# R7FA2A2AD register map
Vendor: Renesas Electronics Corporation; Series: RA2A2; File version: 1.20.02
CPU: CM23 r1p0, little endian, MPU, no FPU, VTOR, 2 interrupt priority bits, 32 interrupts
Registers are 8-bit, read-write, reset 0x0 unless marked. A register's access mark holds for its fields unless they carry their own. Offsets are from the block's base; [hi:lo] are bit positions; {n}, {i} and the like mark numbered series; 'fields as' and 'values as' point back to an identical list.

## RMPU — Renesas Memory Protection Unit
Base 0x40000000
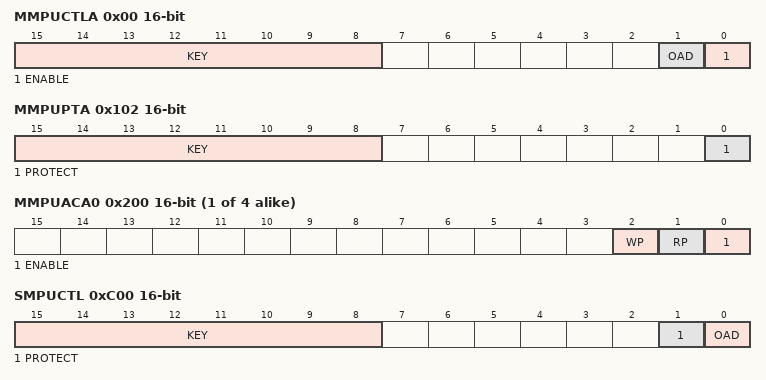
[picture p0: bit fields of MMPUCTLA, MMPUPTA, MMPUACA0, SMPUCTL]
0x00 MMPUCTLA 16-bit — Bus Master MPU Control Register
  [15:8] KEY — Key Code
  [1] OAD — Operation After Detection
  [0] ENABLE — Master Group Enable
0x102 MMPUPTA 16-bit — Group A Protection of Register
  [15:8] KEY — Key Code
  [0] PROTECT — Protection of Register
{0x200+0x10*i} MMPUACA{i} (i=0..3) 16-bit — Group A Region {i} Access Control Register
  [2] WP — Write Protection
  [1] RP — Read Protection
  [0] ENABLE — Region Enable
{0x204+0x10*i} MMPUSA{i} (i=0..3) 32-bit (reset mask 0x3) — Group A Region {i} Start Address Register
  [31:0] MMPUSA — Region Start Address
{0x208+0x10*i} MMPUEA{i} (i=0..3) 32-bit reset 0x3 (reset mask 0x3) — Group A Region {i} End Address Register
  [31:0] MMPUEA — Region End Address
0xC00 SMPUCTL 16-bit — Slave MPU Control Register
  [15:8] KEY — Key Code
  [1] PROTECT — Protection of Register
  [0] OAD — Operation After Detection
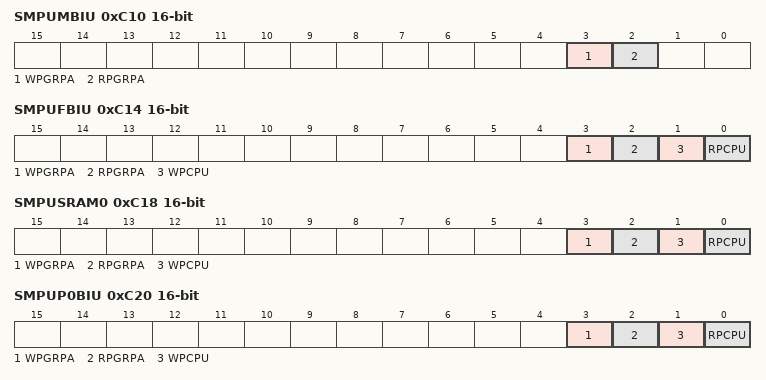
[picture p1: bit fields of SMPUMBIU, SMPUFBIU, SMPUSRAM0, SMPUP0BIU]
0xC10 SMPUMBIU 16-bit — Access Control Register for Memory Bus 1
  [3] WPGRPA — Master MPU Group A Write Protection
  [2] RPGRPA — Master MPU Group A Read Protection
0xC14 SMPUFBIU 16-bit — Access Control Register for Internal Peripheral Bus 9
  [3] WPGRPA — Master MPU Group A Write Protection
  [2] RPGRPA — Master MPU Group A Read Protection
  [1] WPCPU — CPU Write Protection
  [0] RPCPU — CPU Read Protection
0xC18 SMPUSRAM0 16-bit — Access Control Register for Memory Bus 4
  fields as SMPUFBIU
0xC20 SMPUP0BIU 16-bit — Access Control Register for Internal Peripheral Bus 1
  fields as SMPUFBIU
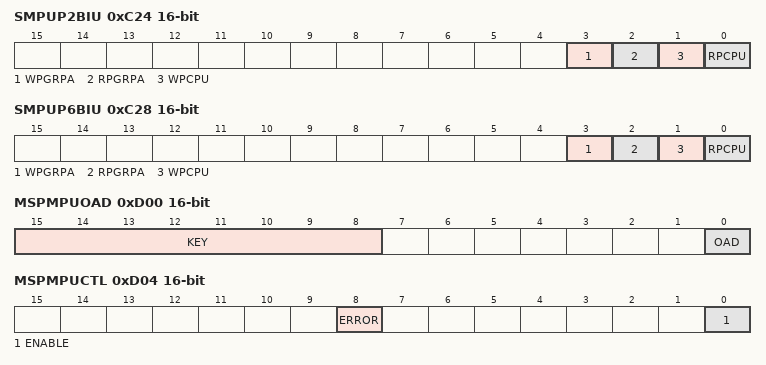
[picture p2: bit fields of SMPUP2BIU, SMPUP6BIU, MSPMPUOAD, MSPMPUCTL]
0xC24 SMPUP2BIU 16-bit — Access Control Register for Internal Peripheral Bus 3
  fields as SMPUFBIU
0xC28 SMPUP6BIU 16-bit — Access Control Register for Internal Peripheral Bus 7
  fields as SMPUFBIU
0xD00 MSPMPUOAD 16-bit — Stack Pointer Monitor Operation After Detection Register
  [15:8] KEY — Key Code
  [0] OAD — Operation after Detection
0xD04 MSPMPUCTL 16-bit (reset mask 0xFEFF) — Stack Pointer Monitor Access Control Register
  [8] ERROR — Stack Pointer Monitor Error Flag
  [0] ENABLE — Stack Pointer Monitor Enable
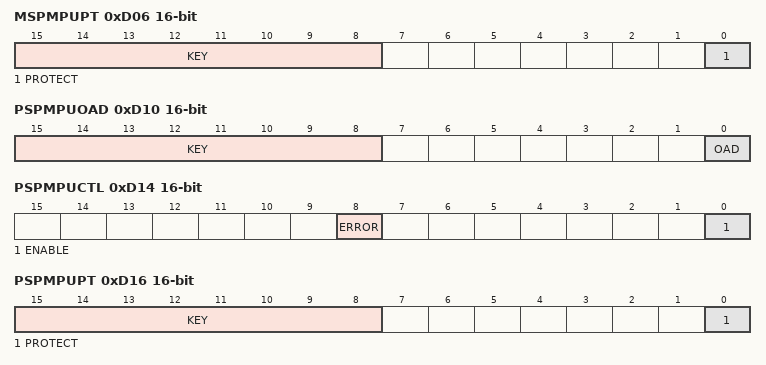
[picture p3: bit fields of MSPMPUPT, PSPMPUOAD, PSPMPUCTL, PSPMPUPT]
0xD06 MSPMPUPT 16-bit — Stack Pointer Monitor Protection Register
  [15:8] KEY — Key Code
  [0] PROTECT — Protection of Register
0xD08 MSPMPUSA 32-bit reset not defined — Main Stack Pointer (MSP) Monitor Start Address Register
  [31:0] MSPMPUSA — Region Start Address
0xD0C MSPMPUEA 32-bit reset not defined — Main Stack Pointer (MSP) Monitor End Address Register
  [31:0] MSPMPUEA — Region End Address
0xD10 PSPMPUOAD 16-bit — Stack Pointer Monitor Operation After Detection Register
  [15:8] KEY — Key Code
  [0] OAD — Operation after Detection
0xD14 PSPMPUCTL 16-bit (reset mask 0xFEFF) — Stack Pointer Monitor Access Control Register
  fields as MSPMPUCTL
0xD16 PSPMPUPT 16-bit — Stack Pointer Monitor Protection Register
  [15:8] KEY — Key Code
  [0] PROTECT — Protection of Register
0xD18 PSPMPUSA 32-bit reset not defined — Process Stack Pointer (PSP) Monitor Start Address Register
  [31:0] PSPMPUSA range 0x1FF00000..0x200FFFFC — Region Start Address
0xD1C PSPMPUEA 32-bit reset not defined — Process Stack Pointer (PSP) Monitor End Address Register
  [31:0] PSPMPUEA range 0x1FF00003..0x200FFFFF — Region End Address

## MMF — Memory Mirror Function
Base 0x40001000
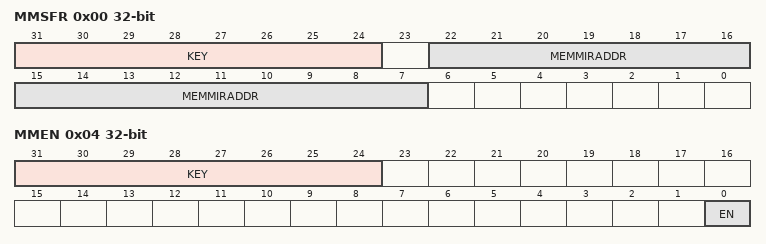
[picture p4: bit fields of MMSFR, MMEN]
0x00 MMSFR 32-bit — MemMirror Special Function Register
  [31:24] KEY wo — MMSFR Key Code
  [22:7] MEMMIRADDR — Memory Mirror Address
0x04 MMEN 32-bit — MemMirror Enable Register
  [31:24] KEY wo — MMEN Key Code
  [0] EN — Memory Mirror Function Enable

## SRAM — SRAM Control
Base 0x40002000
0x00 PARIOAD — SRAM Parity Error Operation After Detection Register
  [0] OAD — Operation After Detection
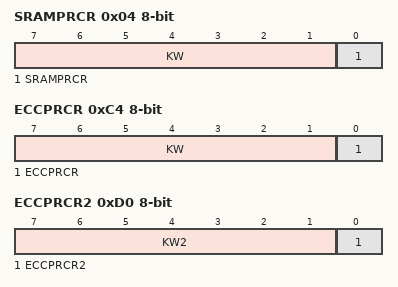
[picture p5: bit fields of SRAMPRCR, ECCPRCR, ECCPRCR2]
0x04 SRAMPRCR — SRAM Protection Register
  [7:1] KW wo — Write Key Code
  [0] SRAMPRCR — Register Write Control
0xC0 ECCMODE — ECC Operating Mode Control Register
  [1:0] ECCMOD — ECC Operating Mode Select
0xC1 ECC2STS — ECC 2-Bit Error Status Register
  [0] ECC2ERR — ECC 2-Bit Error Status
0xC2 ECC1STSEN — ECC 1-Bit Error Information Update Enable Register
  [0] E1STSEN — ECC 1-Bit Error Information Update Enable
0xC3 ECC1STS — ECC 1-Bit Error Status Register
  [0] ECC1ERR — ECC 1-Bit Error Status
0xC4 ECCPRCR — ECC Protection Register
  [7:1] KW wo — Write Key Code
  [0] ECCPRCR — Register Write Control
0xD0 ECCPRCR2 — ECC Protection Register 2
  [7:1] KW2 wo — Write Key Code
  [0] ECCPRCR2 — Register Write Control
0xD4 ECCETST — ECC Test Control Register
  [0] TSTBYP — ECC Bypass Select
0xD8 ECCOAD — SRAM ECC Error Operation After Detection Register
  [0] OAD — Operation After Detection
